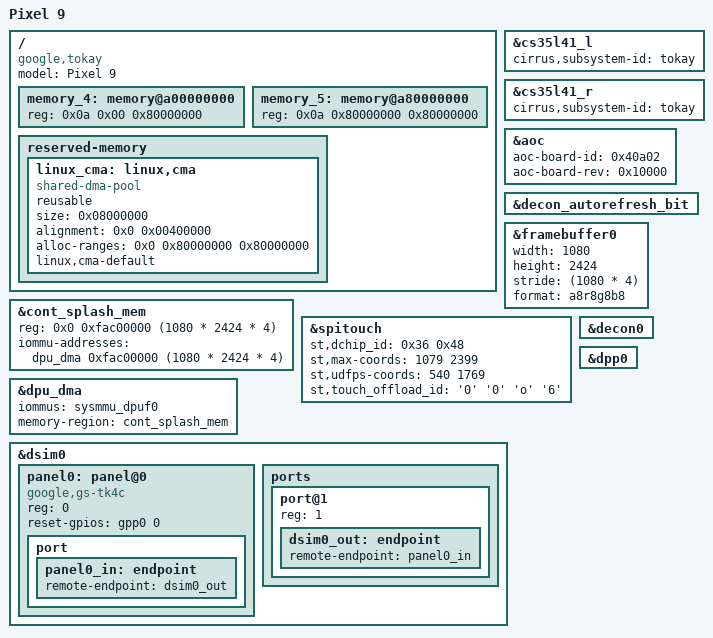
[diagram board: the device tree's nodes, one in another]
// SPDX-License-Identifier: GPL-2.0-only
/*
 * Pixel 9 (tokay) Device Tree
 *
 * Copyright 2025 Trijal Saha - <trijalsaha2012@gmail.com>
 */

/dts-v1/;

#include "zumapro-pixel-common.dtsi"
#include "zumapro-caimito-bcm4390.dtsi"
#include "zumapro-caimito-s5400.dtsi"
#include "zumapro-caimito-cs35l41.dtsi"

/ {
	model = "Pixel 9";
	compatible = "google,tokay", "google,zumapro-tokay", "google,zumapro";

	memory_4: memory@a00000000 {
		device_type = "memory";
		reg = <0x0a 0x00 0x80000000>;
	};

	memory_5: memory@a80000000 {
		device_type = "memory";
		reg = <0x0a 0x80000000 0x80000000>;
	};
	reserved-memory {
		/*
		 * DPU scanout is physically addressed while the SysMMU is kept
		 * detached during bring-up.  Keep enough low memory for several
		 * 1080x2424 buffers and constrain it to the IDMA's 32-bit range.
		 */
		linux_cma: linux,cma {
			compatible = "shared-dma-pool";
			reusable;
			size = <0x08000000>;
			/* "alignment" uses the parent's two address cells. */
			alignment = <0x0 0x00400000>;
			alloc-ranges = <0x0 0x80000000 0x80000000>;
			linux,cma-default;
		};
	};
};

/* Board identity the AOC firmware reads at boot. */
/*
 * The Halo DSP speaker-protection tuning is specific to this board's drivers
 * and to each channel, so the firmware has to be named for both.  This is what
 * wm_adsp interpolates as the system name: the amplifiers ask for
 * cirrus/cs35l41-dsp1-spk-prot-tokay.wmfw, and for a tuning of the same stem
 * with "-r" appended on the right-hand amplifier, which carries the prefix.
 */
&cs35l41_l {
	cirrus,subsystem-id = "tokay";
};

&cs35l41_r {
	cirrus,subsystem-id = "tokay";
};

&aoc {
	aoc-board-id = <0x40a02>;
	aoc-board-rev = <0x10000>;
};

&decon_autorefresh_bit {
	status = "okay";
};

&cont_splash_mem {
	reg = <0x0 0xfac00000 (1080 * 2424 * 4)>;
	/*
	 * Keep the bootloader scanout valid when the DPUF0 SysMMU switches
	 * from bypass to the Linux DMA domain. The direct IOVA mapping is
	 * installed before the domain is attached.
	 */
	iommu-addresses = <&dpu_dma 0xfac00000 (1080 * 2424 * 4)>;
	status = "okay";
};

&framebuffer0 {
	// width = <1440>;
	// height = <3120>;
	// stride = <(1440 * 4)>;
	width = <1080>;
	height = <2424>;
	stride = <(1080 * 4)>;
	format = "a8r8g8b8";
	status = "okay";
};

&spitouch {
	st,dchip_id = /bits/ 8 <0x36 0x48>;
	st,max-coords = <1079 2399>;
	st,udfps-coords = <540 1769>;
	st,touch_offload_id = /bits/ 8 <'0' '0' 'o' '6'>;
};

/*
 * Production Tokay TK4C display. Unlike Komodo, this is 1080x2424 at a
 * 756 Mbps lane rate and uses the TK4C-specific DSC and command sequence.
 */
&decon0 {
	status = "okay";
};

&dpu_dma {
	/*
	 * GF0 is a DPUF0 fetch channel. The identity-mapped splash above
	 * makes attaching its SysMMU safe while the bootloader is scanning
	 * out; subsequent PRIME imports receive contiguous IOVAs.
	 */
	iommus = <&sysmmu_dpuf0>;
	memory-region = <&cont_splash_mem>;
	status = "okay";
};

&dpp0 {
	status = "okay";
};

&dsim0 {
	status = "okay";

	panel0: panel@0 {
		compatible = "google,gs-tk4c";
		reg = <0>;
		reset-gpios = <&gpp0 0 GPIO_ACTIVE_HIGH>;

		port {
			panel0_in: endpoint {
				remote-endpoint = <&dsim0_out>;
			};
		};
	};

	ports {
		port@1 {
			reg = <1>;
			dsim0_out: endpoint {
				remote-endpoint = <&panel0_in>;
			};
		};
	};
};

